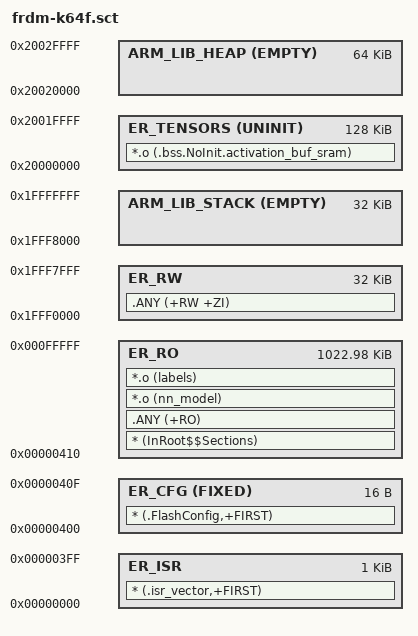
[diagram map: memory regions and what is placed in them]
;  Copyright (c) 2022 Arm Limited. All rights reserved.
;  SPDX-License-Identifier: Apache-2.0
;
;  Licensed under the Apache License, Version 2.0 (the "License");
;  you may not use this file except in compliance with the License.
;  You may obtain a copy of the License at
;
;      http://www.apache.org/licenses/LICENSE-2.0
;
;  Unless required by applicable law or agreed to in writing, software
;  distributed under the License is distributed on an "AS IS" BASIS,
;  WITHOUT WARRANTIES OR CONDITIONS OF ANY KIND, either express or implied.
;  See the License for the specific language governing permissions and
;  limitations under the License.

; *************************************************************
; ***       Scatter-Loading Description File                ***
; *************************************************************

;---------------------------------------------------------
; First load region (ITCM)
;---------------------------------------------------------
LOAD_REGION_FLASH     0x00000000                0x00100000
{
    ;-----------------------------------------------------
    ; First 1K of code mem resevered for ISR Vector
    ;-----------------------------------------------------
    ER_ISR            0x00000000                0x00000400
    {
        * (.isr_vector,+FIRST)
    }

    ;-----------------------------------------------------
    ; 16 byte section reserved for flash configuration
    ;-----------------------------------------------------
    ER_CFG            0x00000400  FIXED         0x00000010
    {
        * (.FlashConfig,+FIRST)
    }

    ;-----------------------------------------------------
    ; RO region - remaining flash used for any RO
    ;-----------------------------------------------------
    ER_RO             0x00000410  ALIGNALL 4    0x000FFBF0
    {
        * (InRoot$$Sections)
        .ANY (+RO)
        *.o (nn_model)
        *.o (labels)
    }

    ;-----------------------------------------------------
    ; 32 KB RW region - SRAM "Lower" (SRAML)
    ;-----------------------------------------------------
    ER_RW             0x1FFF0000  ALIGNALL 4    0x00008000
    {
        .ANY (+RW +ZI)
    }

    ;-----------------------------------------------------
    ; 32 KB stack in remaining part of SRAML, growing down
    ;-----------------------------------------------------
    ARM_LIB_STACK     0x20000000    EMPTY      -0x00008000
    {}

    ;-----------------------------------------------------
    ; Tensor arena placed in SRAM "Upper" (SRAMU) - 128K
    ;-----------------------------------------------------
    ER_TENSORS        0x20000000  UNINIT        0x00020000
    {
        ; Tensor arena for static buffer space required by
        ; TensorFlow Lite Micro
        *.o (.bss.NoInit.activation_buf_sram)
    }

    ;-----------------------------------------------------
    ; 64K heap in the remainder of SRAMU
    ;-----------------------------------------------------
    ARM_LIB_HEAP      0x20020000  EMPTY         0x00010000
    {}
}
